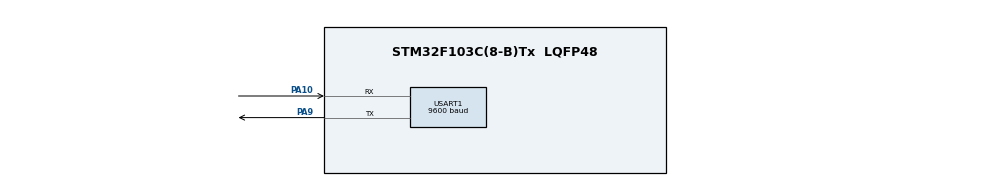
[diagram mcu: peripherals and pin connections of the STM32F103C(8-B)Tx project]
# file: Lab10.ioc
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Mcu.Family=STM32F1
Mcu.Name=STM32F103C(8-B)Tx
Mcu.Package=LQFP48
NVIC.PriorityGroup=NVIC_PRIORITYGROUP_4
NVIC.USART1_IRQn=true\:0\:0\:false\:true\:true\:1\:true\:true\:true
PA10.Mode=Asynchronous
PA10.Signal=USART1_RX
PA9.Mode=Asynchronous
PA9.Signal=USART1_TX
ProjectManager.HeapSize=0x200
ProjectManager.StackSize=0x400
ProjectManager.TargetToolchain=STM32CubeIDE
RCC.APB1Freq_Value=8000000
RCC.APB2Freq_Value=8000000
USART1.BaudRate=9600
USART1.VirtualMode=VM_ASYNC
board=custom

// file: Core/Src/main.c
/* USER CODE BEGIN Header */
/**
  ******************************************************************************
  * @file           : main.c
  * @brief          : Main program body
  ******************************************************************************
  * @attention
  *
  * Copyright (c) 2022 STMicroelectronics.
  * All rights reserved.
  *
  * This software is licensed under terms that can be found in the LICENSE file
  * in the root directory of this software component.
  * If no LICENSE file comes with this software, it is provided AS-IS.
  *
  ******************************************************************************
  */
/* USER CODE END Header */
#include "main.h"

/* USER CODE BEGIN Includes */
#include "string.h"
#include "stdio.h"
/* USER CODE END Includes */

UART_HandleTypeDef huart1;

void SystemClock_Config(void);
static void MX_GPIO_Init(void);
static void MX_USART1_UART_Init(void);
static void MX_NVIC_Init(void);

int main(void)
{

  /* MCU Configuration--------------------------------------------------------*/

  /* Reset of all peripherals, Initializes the Flash interface and the Systick. */
  HAL_Init();

  /* Configure the system clock */
  SystemClock_Config();

  /* Initialize all configured peripherals */
  MX_GPIO_Init();
  MX_USART1_UART_Init();

  /* Initialize interrupts */
  MX_NVIC_Init();
  /* USER CODE BEGIN 2 */
  uint32_t SIZE_ONE_PAGE = 0x400; // розмір сторінки 1 Кб, або 1024 байта
  	uint32_t ADDR_FLASH_PAGE = 0x08000000 + 64 * SIZE_ONE_PAGE; // адреса 64 сторінки 0x0800FC00

  	size_t SIZE_uint32 = sizeof(uint32_t); // 32 біта це 4 байти
  	// в одну сторінку розміром 1Кб можна записати 1024/4=256 змінних розміром 4 байти

  	uint32_t val_000 = 0x01234567;
  	uint32_t val_004 = 0x89ABCDEF;
  	uint32_t val_00C = 0x01020304;
  	uint32_t val_3FC = 0x0000FFFF; //1024-4=1020 == 0x400-0x004=0x3FC

  	HAL_UART_Transmit(&huart1, (uint8_t*)"\n\n\r!!!Erase page 64!!!\n\r", sizeof("\n\n\r!!!Erase page 64!!!\n\r"), 100);
  	Flash_Erase_One_Page(ADDR_FLASH_PAGE); // очищення 64 сторінки

  	HAL_UART_Transmit(&huart1, (uint8_t*)"\n!!!Write!!!\n\r", sizeof("\n!!!Write!!!\n\r"), 100);
  	// запис значень на початку і в кінці 127 сторінки
  	Flash_Write_uint32(ADDR_FLASH_PAGE + 0 * SIZE_uint32, val_000);
  	Flash_Write_uint32(ADDR_FLASH_PAGE + 1 * SIZE_uint32, val_004);
  	Flash_Write_uint32(ADDR_FLASH_PAGE + 3 * SIZE_uint32, val_00C);
  	Flash_Write_uint32(ADDR_FLASH_PAGE + 255 * SIZE_uint32, val_3FC);

  	HAL_UART_Transmit(&huart1, (uint8_t*)"\n!!!Erase page 63!!!\n\r", sizeof("\n!!!Erase page 63!!!\n\r"), 100);
  	Flash_Erase_One_Page(ADDR_FLASH_PAGE - SIZE_ONE_PAGE); // очищення 63 сторінки

  	HAL_UART_Transmit(&huart1, (uint8_t*)"\n!!!Write!!!\n\r", sizeof("\n!!!Write!!!\n\r"), 100);
  	// запис значень на початку і в кінці 126 сторінки
  	Flash_Write_uint32(ADDR_FLASH_PAGE - SIZE_ONE_PAGE + 0x000, val_000);
  Flash_Write_uint32(ADDR_FLASH_PAGE - SIZE_ONE_PAGE + 0x004, val_004);
  	Flash_Write_uint32(ADDR_FLASH_PAGE - SIZE_ONE_PAGE + 0x00C, val_00C);
  	Flash_Write_uint32(ADDR_FLASH_PAGE - SIZE_ONE_PAGE + 0x3FC, val_3FC);

  	HAL_UART_Transmit(&huart1, (uint8_t*)"\n!!!Read!!!\n\r", sizeof("\n!!!Read!!!\n\r"), 100);
  	// читання значень з 64 сторінки Flash-пам'яті
  	uint32_t a = Flash_Read_uint32(ADDR_FLASH_PAGE + 0 * SIZE_uint32);
  	uint32_t b = Flash_Read_uint32(ADDR_FLASH_PAGE + 1 * SIZE_uint32);
  	uint32_t c = Flash_Read_uint32(ADDR_FLASH_PAGE + 3 * SIZE_uint32);
  	uint32_t d = Flash_Read_uint32(ADDR_FLASH_PAGE + 255 * SIZE_uint32);

  /* USER CODE END 2 */

  /* Infinite loop */
  while (1)
  {

  }
}

void SystemClock_Config(void)
{
  RCC_OscInitTypeDef RCC_OscInitStruct = {0};
  RCC_ClkInitTypeDef RCC_ClkInitStruct = {0};

  /** Initializes the RCC Oscillators according to the specified parameters
  * in the RCC_OscInitTypeDef structure.
  */
  RCC_OscInitStruct.OscillatorType = RCC_OSCILLATORTYPE_HSI;
  RCC_OscInitStruct.HSIState = RCC_HSI_ON;
  RCC_OscInitStruct.HSICalibrationValue = RCC_HSICALIBRATION_DEFAULT;
  RCC_OscInitStruct.PLL.PLLState = RCC_PLL_NONE;
  if (HAL_RCC_OscConfig(&RCC_OscInitStruct) != HAL_OK)
  {
    Error_Handler();
  }

  /** Initializes the CPU, AHB and APB buses clocks
  */
  RCC_ClkInitStruct.ClockType = RCC_CLOCKTYPE_HCLK|RCC_CLOCKTYPE_SYSCLK
                              |RCC_CLOCKTYPE_PCLK1|RCC_CLOCKTYPE_PCLK2;
  RCC_ClkInitStruct.SYSCLKSource = RCC_SYSCLKSOURCE_HSI;
  RCC_ClkInitStruct.AHBCLKDivider = RCC_SYSCLK_DIV1;
  RCC_ClkInitStruct.APB1CLKDivider = RCC_HCLK_DIV1;
  RCC_ClkInitStruct.APB2CLKDivider = RCC_HCLK_DIV1;

  if (HAL_RCC_ClockConfig(&RCC_ClkInitStruct, FLASH_LATENCY_0) != HAL_OK)
  {
    Error_Handler();
  }
}

/**
  * @brief NVIC Configuration.
  * @retval None
  */
static void MX_NVIC_Init(void)
{
  /* USART1_IRQn interrupt configuration */
  HAL_NVIC_SetPriority(USART1_IRQn, 0, 0);
  HAL_NVIC_EnableIRQ(USART1_IRQn);
}

static void MX_USART1_UART_Init(void)
{

  huart1.Instance = USART1;
  huart1.Init.BaudRate = 9600;
  huart1.Init.WordLength = UART_WORDLENGTH_8B;
  huart1.Init.StopBits = UART_STOPBITS_1;
  huart1.Init.Parity = UART_PARITY_NONE;
  huart1.Init.Mode = UART_MODE_TX_RX;
  huart1.Init.HwFlowCtl = UART_HWCONTROL_NONE;
  huart1.Init.OverSampling = UART_OVERSAMPLING_16;
  if (HAL_UART_Init(&huart1) != HAL_OK)
  {
    Error_Handler();
  }

}

static void MX_GPIO_Init(void)
{

  /* GPIO Ports Clock Enable */
  __HAL_RCC_GPIOA_CLK_ENABLE();

}

/* USER CODE BEGIN 4 */
void Flash_Erase_One_Page(uint32_t MYADDR)
{
	FLASH_EraseInitTypeDef EraseInitStruct; // структура для очищення флеша

	EraseInitStruct.TypeErase = FLASH_TYPEERASE_PAGES; // очищення сторінками, FLASH_TYPEERASE_MASSERASE - очищення всього флеша
	EraseInitStruct.PageAddress = MYADDR; // адреса сторінки;
	EraseInitStruct.NbPages = 1;          // кількість сторінок для очищення
	//EraseInitStruct.Banks = FLASH_BANK_1; // для більш потужник МК ніж STM32F103

	uint32_t page_error = 0; // змінна в яку запишеться адреса сторінки, при невдалому очищенні

	char str[64] = { 0, };

	//////// ОЧИЩЕННЯ Flash-пам'яті ////////
	HAL_FLASH_Unlock(); // розблокування Flash-пам'яті

	if (HAL_FLASHEx_Erase(&EraseInitStruct, &page_error) != HAL_OK)
	{
		// сталась помилка при очищенні сторінки
		uint32_t er = HAL_FLASH_GetError();
		snprintf(str, 64, "Error Flash_Erase(): %lu\n\r", er);
		HAL_UART_Transmit(&huart1, (uint8_t*) str, strlen(str), 100);
		while (1)
		{
		}
	}

	// очищення сторінки виконане успішно
	snprintf(str, 64, "Erase Flash from address 0x%08lX to address 0x%08lX OK\n\r", MYADDR, MYADDR+0x400-1);
	HAL_UART_Transmit(&huart1, (uint8_t*) str, strlen(str), 100);

	HAL_FLASH_Lock(); // заблокування Flash-пам'яті
}

void Flash_Write_uint32(uint32_t MYADDR, uint32_t val)
{
	char str[64] = { 0, };

	///////////// ЗАПИС у Flash-пам'ять ///////////////
	HAL_FLASH_Unlock(); // розблокування Flash-пам'яті

	if (HAL_FLASH_Program(FLASH_TYPEPROGRAM_WORD, MYADDR, val) != HAL_OK)
	{
		uint32_t er = HAL_FLASH_GetError();
		snprintf(str, 64, "Error Flash_Write(): %lu\n\r", er);
		HAL_UART_Transmit(&huart1, (uint8_t*) str, strlen(str), 100);
		while (1)
		{
		}
	}

	snprintf(str, 64, "Write 32 bits (Hex: 0x%08lX) to address 0x%08lX OK\n\r", val, MYADDR);
	HAL_UART_Transmit(&huart1, (uint8_t*) str, strlen(str), 100);

	HAL_FLASH_Lock(); // заблокування Flash-пам'яті
}

uint32_t Flash_Read_uint32(uint32_t MYADDR)
{
	char str[64] = { 0, };

	/////////////// ЧИТАЄМО Flash-пам'ять ///////////////////
	uint32_t dig32 = *(uint32_t*) MYADDR; // читання числа за його адресою

	snprintf(str, 64, "Read 32 bits (Dec: %lu \tHex: 0x%08lX)", dig32, dig32);
	HAL_UART_Transmit(&huart1, (uint8_t*) str, strlen(str), 100);
	snprintf(str, 64, " from address 0x%08lX \n\r", MYADDR);
	HAL_UART_Transmit(&huart1, (uint8_t*) str, strlen(str), 100);

	return dig32;
}

/* USER CODE END 4 */

void Error_Handler(void)
{
  __disable_irq();
  while (1)
  {
  }
}
